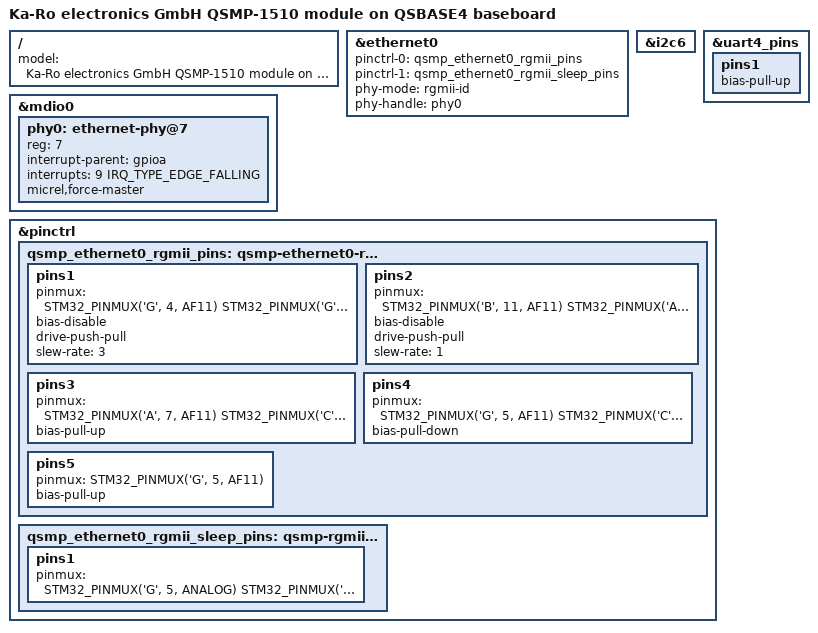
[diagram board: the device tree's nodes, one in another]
// SPDX-License-Identifier: (GPL-2.0-only OR BSD-3-Clause)
/*
 * Copyright (C) 2022 Lothar Waßmann <LW@KARO-electronics.de>
 */

#include "stm32mp151a-qsmp-1510.dts"

/ {
	model = "Ka-Ro electronics GmbH QSMP-1510 module on QSBASE4 baseboard";
};

&ethernet0 {
	pinctrl-names = "default", "sleep";
	pinctrl-0 = <&qsmp_ethernet0_rgmii_pins>;
	pinctrl-1 = <&qsmp_ethernet0_rgmii_sleep_pins>;
	phy-mode = "rgmii-id";
	phy-handle = <&phy0>;
	status = "okay";
};

&i2c6 {
	status = "okay";
};

&mdio0 {
	phy0: ethernet-phy@7 {
		reg = <7>;
		interrupt-parent = <&gpioa>;
		interrupts = <9 IRQ_TYPE_EDGE_FALLING>;
		micrel,force-master;
	};
};

&uart4_pins {
	pins1 {
		/delete-property/ bias-disable;
		bias-pull-up;
	};
};

&pinctrl {
	qsmp_ethernet0_rgmii_pins: qsmp-ethernet0-rgmii-pins {
		pins1 {
			pinmux = <
				  STM32_PINMUX('G', 4, AF11) /* ETH_RGMII_GTX_CLK */
				  STM32_PINMUX('G', 13, AF11) /* ETH_RGMII_TXD0 */
				  STM32_PINMUX('G', 14, AF11) /* ETH_RGMII_TXD1 */
				  STM32_PINMUX('C', 2, AF11) /* ETH_RGMII_TXD2 */
				  STM32_PINMUX('B', 8, AF11) /* ETH_RGMII_TXD3 */
			>;
			bias-disable;
			drive-push-pull;
			slew-rate = <3>;
		};

		pins2 {
			pinmux = <
				  STM32_PINMUX('B', 11, AF11) /* ETH_RGMII_TX_CTL */
				  STM32_PINMUX('A', 2, AF11) /* ETH_MDIO */
				  STM32_PINMUX('C', 1, AF11) /* ETH_MDC */
			>;
			bias-disable;
			drive-push-pull;
			slew-rate = <1>;
		};

		pins3 {
			/* Micrel KSZ9131 strap pins */
			pinmux = <
				  STM32_PINMUX('A', 7, AF11) /* RX_CTL | CLK125_EN */
				  STM32_PINMUX('C', 5, AF11) /* RXD1 | MODE1 */
				  STM32_PINMUX('B', 0, AF11) /* RXD2 | MODE2 */
				  STM32_PINMUX('H', 7, AF11) /* RXD3 | MODE3 */
				  STM32_PINMUX('A', 1, AF11) /* RX_CLK | PHYAD2 */
			>;
			bias-pull-up;
		};

		pins4 {
			pinmux = <
				  STM32_PINMUX('G', 5, AF11) /* CLK125 | LED_MODE */
				  STM32_PINMUX('C', 4, AF11) /* RXD0 | MODE0 */
			>;
			bias-pull-down;
		};

		pins5 {
			pinmux = <
				  STM32_PINMUX('G', 5, AF11) /* CLK125 | LED_MODE */
			>;
			bias-pull-up;
		};
	};

	qsmp_ethernet0_rgmii_sleep_pins: qsmp-rgmii-sleep-pins {
		pins1 {
			pinmux = <
				  STM32_PINMUX('G', 5, ANALOG) /* ETH_RGMII_CLK125 */
				  STM32_PINMUX('G', 4, ANALOG) /* ETH_RGMII_GTX_CLK */
				  STM32_PINMUX('G', 13, ANALOG) /* ETH_RGMII_TXD0 */
				  STM32_PINMUX('G', 14, ANALOG) /* ETH_RGMII_TXD1 */
				  STM32_PINMUX('C', 2, ANALOG) /* ETH_RGMII_TXD2 */
				  STM32_PINMUX('B', 8, ANALOG) /* ETH_RGMII_TXD3 */
				  STM32_PINMUX('B', 11, ANALOG) /* ETH_RGMII_TX_CTL */
				  STM32_PINMUX('A', 2, ANALOG) /* ETH_MDIO */
				  STM32_PINMUX('C', 1, ANALOG) /* ETH_MDC */
				  STM32_PINMUX('C', 4, ANALOG) /* ETH_RGMII_RXD0 */
				  STM32_PINMUX('C', 5, ANALOG) /* ETH_RGMII_RXD1 */
				  STM32_PINMUX('B', 0, ANALOG) /* ETH_RGMII_RXD2 */
				  STM32_PINMUX('H', 7, ANALOG) /* ETH_RGMII_RXD3 */
				  STM32_PINMUX('A', 1, ANALOG) /* ETH_RGMII_RX_CLK */
				  STM32_PINMUX('A', 7, ANALOG) /* ETH_RGMII_RX_CTL */
			>;
		};
	};
};
